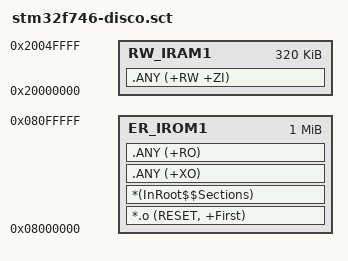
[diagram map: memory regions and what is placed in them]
;  Copyright (c) 2021-2022 Arm Limited. All rights reserved.
;  SPDX-License-Identifier: Apache-2.0
;
;  Licensed under the Apache License, Version 2.0 (the "License");
;  you may not use this file except in compliance with the License.
;  You may obtain a copy of the License at
;
;      http://www.apache.org/licenses/LICENSE-2.0
;
;  Unless required by applicable law or agreed to in writing, software
;  distributed under the License is distributed on an "AS IS" BASIS,
;  WITHOUT WARRANTIES OR CONDITIONS OF ANY KIND, either express or implied.
;  See the License for the specific language governing permissions and
;  limitations under the License.

;               load region   size_region
LOAD_REGION_0   0x08000000  0x100000
{
  ER_IROM1      0x08000000  0x00100000 { ; load address = execution address
   *.o (RESET, +First)
   *(InRoot$$Sections)
   .ANY (+XO)
   .ANY (+RO)
  }

  RW_IRAM1 0x20000000 ALIGNALL 4 0x50000 {
   .ANY (+RW +ZI)
  }
}
